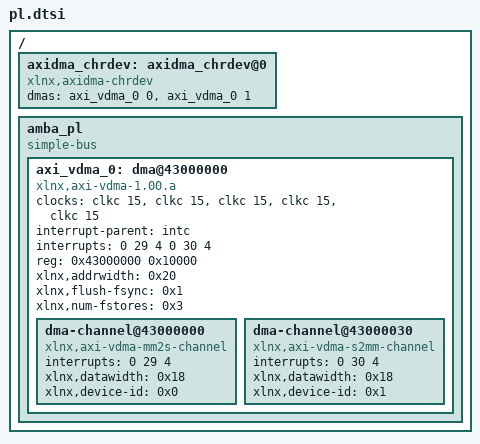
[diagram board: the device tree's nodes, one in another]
/*
 * CAUTION: This file is automatically generated by Xilinx.
 * Version:  
 * Today is: Thu Nov 23 11:40:16 2017
*/


/ {
  axidma_chrdev: axidma_chrdev@0 {
      compatible = "xlnx,axidma-chrdev";
      dmas = <&axi_vdma_0 0 &axi_vdma_0 1>;
      dma-names = "tx_channel", "rx_channel";
  };
	amba_pl: amba_pl {
		#address-cells = <1>;
		#size-cells = <1>;
		compatible = "simple-bus";
		ranges ;
		axi_vdma_0: dma@43000000 {
			#dma-cells = <1>;
			clock-names = "s_axi_lite_aclk", "m_axi_mm2s_aclk", "m_axi_mm2s_aclk", "m_axi_s2mm_aclk", "m_axi_s2mm_aclk";
			clocks = <&clkc 15>, <&clkc 15>, <&clkc 15>, <&clkc 15>, <&clkc 15>;
			compatible = "xlnx,axi-vdma-1.00.a";
			interrupt-parent = <&intc>;
			interrupts = <0 29 4 0 30 4>;
			reg = <0x43000000 0x10000>;
			xlnx,addrwidth = <0x20>;
			xlnx,flush-fsync = <0x1>;
			xlnx,num-fstores = <0x3>;
			dma-channel@43000000 {
				compatible = "xlnx,axi-vdma-mm2s-channel";
				interrupts = <0 29 4>;
				xlnx,datawidth = <0x18>;
				xlnx,device-id = <0x0>;
			};
			dma-channel@43000030 {
				compatible = "xlnx,axi-vdma-s2mm-channel";
				interrupts = <0 30 4>;
				xlnx,datawidth = <0x18>;
				xlnx,device-id = <0x1>;
			};
		};
	};
};
